AUTOSAR XML (schema 00047)
package /MICROSAR/Os_swc/DataTypes
  impl type TimeInMicrosecondsType: range raw 0..4294967295, implementation-data-type=uint32
  impl type CounterType: range raw 0..255, implementation-data-type=uint8, type-emitter=Os
package /MICROSAR/Os_swc/Interfaces
  client server interface Os_Service: is-service=true, service-kind=OPERATING-SYSTEM
    operation GetCounterValue: possible-error=[E_OK, E_OS_ID]  # This service reads the current count value of a counter (returning either the hardware timer ticks if counter is driven by hardware or the software ticks when user drives counter).
      arg Value: type=TimeInMicrosecondsType, direction=OUT
    operation GetElapsedValue: possible-error=[E_OK, E_OS_ID, E_OS_VALUE]  # This service gets the number of ticks between the current tick value and a previously read tick value.
      arg Value: type=TimeInMicrosecondsType, direction=INOUT
      arg ElapsedValue: type=TimeInMicrosecondsType, direction=OUT
    5 x error:
      E_OK: error-code=0
      E_OS_ACCESS: error-code=1
      E_OS_ID: error-code=3
      E_OS_STATE: error-code=7
      E_OS_VALUE: error-code=8
package /MICROSAR/Os_swc/ComponentTypes
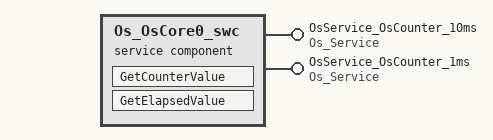
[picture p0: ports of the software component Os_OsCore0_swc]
  service sw component type Os_OsCore0_swc: category=SERVICE_COMPONENT
    provide port OsService_OsCounter_10ms: provided-interface=Os_Service
    provide port OsService_OsCounter_1ms: provided-interface=Os_Service
    behavior Os_OsCore0_swcInternalBehavior: handle-termination-and-restart=NO-SUPPORT
      4 x operation invoked event:
        OpEventGetCounterValue_GetCounterValue_OsService_OsCounter_10ms: start-on-event=GetCounterValue, operation=OsService_OsCounter_10ms.GetCounterValue
        OpEventGetElapsedValue_GetElapsedValue_OsService_OsCounter_10ms: start-on-event=GetElapsedValue, operation=OsService_OsCounter_10ms.GetElapsedValue
        OpEventGetCounterValue_GetCounterValue_OsService_OsCounter_1ms: start-on-event=GetCounterValue, operation=OsService_OsCounter_1ms.GetCounterValue
        OpEventGetElapsedValue_GetElapsedValue_OsService_OsCounter_1ms: start-on-event=GetElapsedValue, operation=OsService_OsCounter_1ms.GetElapsedValue
      port-api-options:
        {enable-take-address=true, indirect-api=false, port-defined-argument-value{value=OsCounter_10ms, value-type=CounterType}, port=OsService_OsCounter_10ms}
        {enable-take-address=true, indirect-api=false, port-defined-argument-value{value=OsCounter_1ms, value-type=CounterType}, port=OsService_OsCounter_1ms}
      runnable GetCounterValue: can-be-invoked-concurrently=true
      runnable GetElapsedValue: can-be-invoked-concurrently=true
  swc implementation Os_OsCore0_swcImplementation: programming-language=C, behavior=Os_OsCore0_swcInternalBehavior
